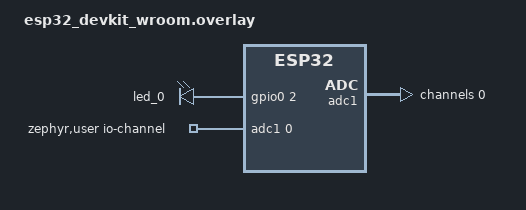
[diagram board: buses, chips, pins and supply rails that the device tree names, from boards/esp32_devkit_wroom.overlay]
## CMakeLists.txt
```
cmake_minimum_required(VERSION 3.20.0)

set(BOARD esp32_devkitc_wroom)
set(DTO_DIR ${CMAKE_CURRENT_SOURCE_DIR}/boards)
set(DTC_OVERLAY_FILE ${DTO_DIR}/esp32_devkit_wroom.overlay)
find_package(Zephyr REQUIRED HINTS $ENV{ZEPHYR_BASE})

project(adc)

target_sources(app PRIVATE src/main.c)
```

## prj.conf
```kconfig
CONFIG_ESP32_USE_UNSUPPORTED_REVISION=y
CONFIG_STDOUT_CONSOLE=y
CONFIG_GPIO=y
CONFIG_ADC=y
```

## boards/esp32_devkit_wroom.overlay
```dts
/{
    leds {
        compatible = "gpio-leds";
        led_0:led_0 {
            gpios = <&gpio0 2 GPIO_ACTIVE_HIGH>;
        };
    };

    zephyr,user {
		io-channels = <&adc1 0>;
	};
};



&adc1 {
    status = "okay";
    #address-cells = <1>;
	#size-cells = <0>;

    channel@0 {
        reg = <0>;
        zephyr,gain = "ADC_GAIN_1";
        zephyr,reference = "ADC_REF_INTERNAL";
        zephyr,acquisition-time = <ADC_ACQ_TIME_DEFAULT>;
        zephyr,resolution = <12>;
        zephyr,oversampling = <8>;
    };
};
```

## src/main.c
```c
#include <inttypes.h>
#include <stddef.h>
#include <stdint.h>

#include <zephyr/device.h>
#include <zephyr/devicetree.h>
#include <zephyr/drivers/adc.h>
#include <zephyr/kernel.h>
#include <zephyr/sys/printk.h>
#include <zephyr/sys/util.h>
#include <zephyr/drivers/gpio.h>

static const struct gpio_dt_spec led = GPIO_DT_SPEC_GET(DT_NODELABEL(led_0),gpios);
static const struct adc_dt_spec adc_ch0 =  ADC_DT_SPEC_GET_BY_IDX(DT_PATH(zephyr_user), 0);


void main(void) {
    int ret = 0;
    if(!device_is_ready(led.port)){
        return;
    }else{
        ret = gpio_pin_configure_dt(&led,GPIO_OUTPUT);  
        if(ret < 0){
            return;
        }else{
            // just to dont leave a if withou else ;p            
        }
    }

     if(!device_is_ready(adc_ch0.dev)){
        return;
    }else{
        ret = adc_channel_setup_dt(&adc_ch0);
		if (ret < 0) {
			printk("Could not setup channel (%d)\n", ret);
			return 0;
		}else{
            printk("ADC READY TO READ SAMPLES\n");
        }
    }

    uint16_t sample;
    struct adc_sequence sequence = {
		.buffer = &sample,
		.buffer_size = sizeof(sample),
	};

    adc_sequence_init_dt(&adc_ch0,&sequence);

    int32_t val;
    while (1) {
        adc_channel_setup_dt(&adc_ch0);
        k_sleep(K_USEC(100));
        gpio_pin_toggle_dt(&led);
        ret = adc_read_dt(&adc_ch0,&sequence);  
        if(ret < 0){
            printk("\nERROR TO READ DATA");
        }
        val = (int32_t)sample;
        printk("\nVALUE READED: %d", sample);

        if (adc_ch0.channel_cfg.differential) {
				val = (int32_t)((int16_t)sample);
		} else {
			val = (int32_t)sample;
		}
        k_sleep(K_MSEC(100));

    }
}
```
